# DP32G030 register map
File version: 1.0
CPU: CM0 r0p0, little endian, no MPU, no FPU, 4 interrupt priority bits
Registers are 32-bit, read-write, reset 0x0 unless marked. A register's access mark holds for its fields unless they carry their own. Offsets are from the block's base; [hi:lo] are bit positions.

## UART0 — UART0 unit
Base 0x4006B000
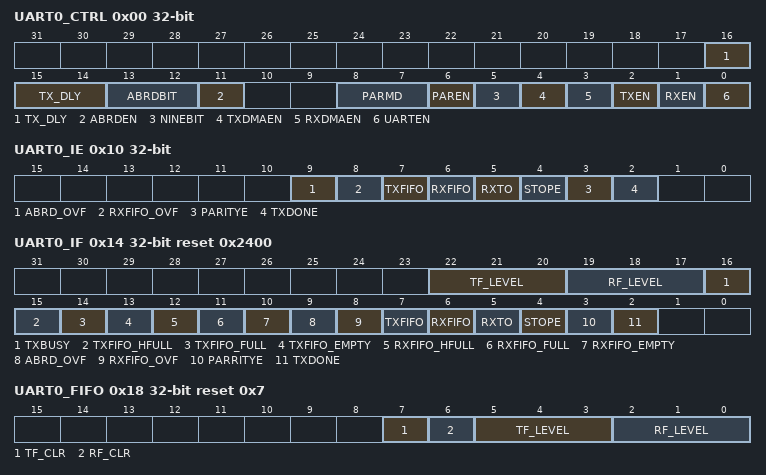
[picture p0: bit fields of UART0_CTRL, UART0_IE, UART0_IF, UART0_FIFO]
0x00 UART0_CTRL — UART control register
  [16:14] TX_DLY — Transmit delay time setting (used to set the transmission delay time between the last stop bit and the next start bit) 000: No delay 001: 1bit delay 010: 2bit delay ...... 111: 7bit delay
  [13:12] ABRDBIT — Automatic baud rate detection bit length configuration 11: 8-bit duration from the start bit to the first rising edge. Input data is 0x80. 10: 4-bit duration from the start bit to the first rising edge. The input data is 0x08. 01: 2-bit duration from the start bit to the first rising edge. Input data is 0x02. 00: 1-bit duration from the start bit to the first rising edge. The input data is 0x01.
  [11] ABRDEN — Auto baud rate detection enable 1: Automatic baud rate detection function enabled 0: Automatic baud rate detection function disabled This bit will be automatically cleared after the auto-detect is finished.
  [8:7] PARMD — Parity mode selection 11: Standing 0 10: Standing 1 01: Even Check 00: odd calibration
  [6] PAREN — Parity bit enable 1: with parity bit 0: without parity bit
  [5] NINEBIT — 9bit data mode enable 1: 9bit data mode 0: 8bit data mode
  [4] TXDMAEN — Send DMA Transmit Enable 1: Indicates the transmit data register for DMA operation of the UART. 0: Indicates that the CPU operates the transmit data register of the UART.
  [3] RXDMAEN — Receive DMA Transmit Enable 1: Indicates the receive data register for DMA operation of the UART. 0: Indicates that the CPU operates the receive data register of the UART.
  [2] TXEN — transmit enable bit 1: Send open. Sends the data stored in tx_fifo through uart_tx. 0: Transmit off. No data is sent. uart_tx signal is held at 1.
  [1] RXEN — receive enable bit (computing) 1: Receive open. External data can be received via uart_rx 0: Receive off. Do not receive data from uart_rx
  [0] UARTEN — UART Enable Bit 1: Enable UART Module 0: Disable UART module
0x04 UART0_BAUD — UART Baud Rate Configuration Register
  [15:0] BAUD — Baud rate configuration data
0x08 UART0_TDR wo — UART write data register
  [8:0] TDR — Write Data Register The data to be sent is written to the transmit FIFO through this register. When the data is ready to be sent, the shift register reads the transmit FIFO directly to send the data.
0x0C UART0_RDR ro — UART read data register
  [8:0] RDR — The received data is read out through this register. The shift register stores data into the receive FIFO after each transmission is completed, and the data in the receive FIFO is read out through this register. Note: If a parity bit error or a stop bit error occurs, the set of data will not be written to the RXFIFO.if the RXFIFO is not empty, the data in the RXFIFO is valid data.
0x10 UART0_IE — UART interrupt enable register
  [9] ABRD_OVF — Auto baud rate detection function Counter overflow interrupt enable
  [8] RXFIFO_OVF — Receive FIFO overflow interrupt enable
  [7] TXFIFO — Send the data stored in FIFO to reach the set water level Interrupt Enable
  [6] RXFIFO — Receive data received in FIFO reaches the set water level Interrupt enable
  [5] RXTO — Receive timeout interrupt enable
  [4] STOPE — Stop bit error interrupt enable for receive data
  [3] PARITYE — Receive data with parity error interrupt enable
  [2] TXDONE — All data sent interrupt enable (indicates that the data in the send shift register has been sent and there is no more data to be sent in the send data FIFO)
0x14 UART0_IF access per field reset 0x2400 — UART Interrupt Status Register
  [22:20] TF_LEVEL ro — Send FIFO water level flag signal 000: If the FIFO is not full, it means there is 0 data in the FIFO, and if it is full, it means The FIFO has 8 data; 001: Indicates that the FIFO has 1 data; ...... 111: Indicates that the FIFO has 7 data;
  [19:17] RF_LEVEL ro — Receive FIFO water level flag signal 000: If the FIFO is not full, it means there is 0 data in the FIFO, and if it is full, it means The FIFO has 8 data; 001: Indicates that the FIFO has 1 data; ...... 111: Indicates that the FIFO has 7 data;
  [16] TXBUSY ro — Data transmission busy flag 1: Transmit FIFO is not empty, or there is data being sent. 0: Transmit FIFO is empty and there is no data being sent.
  [15] TXFIFO_HFULL ro — Send FIFO half full flag
  [14] TXFIFO_FULL ro — Send FIFO full flag
  [13] TXFIFO_EMPTY ro — Send FIFO Empty Flag
  [12] RXFIFO_HFULL ro — Receive FIFO half-full flag
  [11] RXFIFO_FULL ro — Receive FIFO full flag
  [10] RXFIFO_EMPTY ro — Receive FIFO empty flag
  [9] ABRD_OVF rw write-1-clears — Automatic baud rate detection function Counter overflow flag 1: Counter overflow, detection failure 0: Counter not overflowed write 1 Clear
  [8] RXFIFO_OVF rw write-1-clears — Receive FIFO Overflow Flag Write 1 Clear Note: Data after overflow will be discarded
  [7] TXFIFO ro — When the data stored in the transmit FIFO reaches the set water level, the bit is 1, otherwise 0
  [6] RXFIFO ro — When the data received in the receive FIFO reaches the set water level, the bit 1, otherwise 0
  [5] RXTO rw — Receive Timeout Flag 1: Send Receive Timeout Write 1 Clear
  [4] STOPE rw write-1-clears — Stop bit error in receive data Write 1 Clear The main point is that the stop bit is not received or recognized within the expected time period, then it is considered a stop bit error
  [3] PARRITYE rw — Parity error in received data 1 clear
  [2] TXDONE rw — All data transmission is complete (indicates that data transmission in the transmit shift register is complete and there is no pending data in the transmit data FIFO) Write 1 to clear the data.
0x18 UART0_FIFO reset 0x7 — UART FIFO control register
  [7] TF_CLR write-1-clears — TXFIFO clear enable Software Write 1 Clear Transmit FIFO, Hardware Auto Clear
  [6] RF_CLR write-1-clears — RXFIFO clear enable Software Write 1 Clear Receive FIFO, Hardware Auto Clear
  [5:3] TF_LEVEL — Water level setting for TXFIFO generating interrupts 000: 0 001: 1 010:2 ...... 111:7 Indicates that the number of data to be sent in the sending FIFO is not more than the water level setting. For example, if the value 011 is set, the corresponding signal is generated when the number of written data in TXFIFO is less than or equal to 3.
  [2:0] RF_LEVEL — Water level setting for RXFIFO generating interrupts 000: 1 001: 2 010: 3 ...... 111: 8 Indicates that the number of received data in the receive FIFO has reached at least the water level setting. For example, if the value 011 is set, the corresponding signal is generated when there are at least 4 data in the RXFIFO.
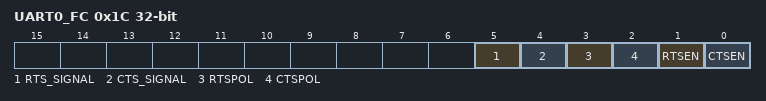
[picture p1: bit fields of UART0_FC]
0x1C UART0_FC access per field — UART Flow Control Configuration Register
  [5] RTS_SIGNAL ro — Indicates RTS status on the line 1: RTS is high 0: RTS is low
  [4] CTS_SIGNAL ro — Indicates online CTS status 1: CTS is high 0: CTS is low
  [3] RTSPOL rw — RTS Signal Polarity Configuration 1: When RTS signal is high, UART can receive data; when RTS signal is low, UART receive FIFO is full and can not receive data. 0: When RTS signal output is low, UART can receive data; when RTS signal output is high, UART receive FIFO is full and no more data can be received.
  [2] CTSPOL rw — CTS Signal Polarity Configuration 1: When the CTS signal input is high, the UART can send data; when the CTS signal input is low, the UART does not send data. 0: When CTS signal input is low, UART can send data; when CTS signal input is high, UART does not send data.
  [1] RTSEN rw — RTS flow control enable 1: RTS signaling plays a flow control role 0: RTS signal does not work
  [0] CTSEN rw — CTS flow control enable 1: CTS signaling plays a flow control role 0: CTS signal does not work
0x20 UART0_RXTO reset 0xFF — UART Receive Timeout Configuration Register
  [7:0] RXTO — Receive Data Timeout Trigger Comparison Value When the RXFIFO receives a new piece of data, the timer is cleared and timing restarts (the timing clock is the duration of a piece of data). A receive timeout flag is generated if a valid start bit has not been received by the time the timer has timed out past this configured value.

## UART1 — UART1 unit
Base 0x4006B800
Registers as UART0 (with UART0 read as UART1).

## UART2 — UART2 unit
Base 0x4006C000
Registers as UART0 (with UART0 read as UART2).
